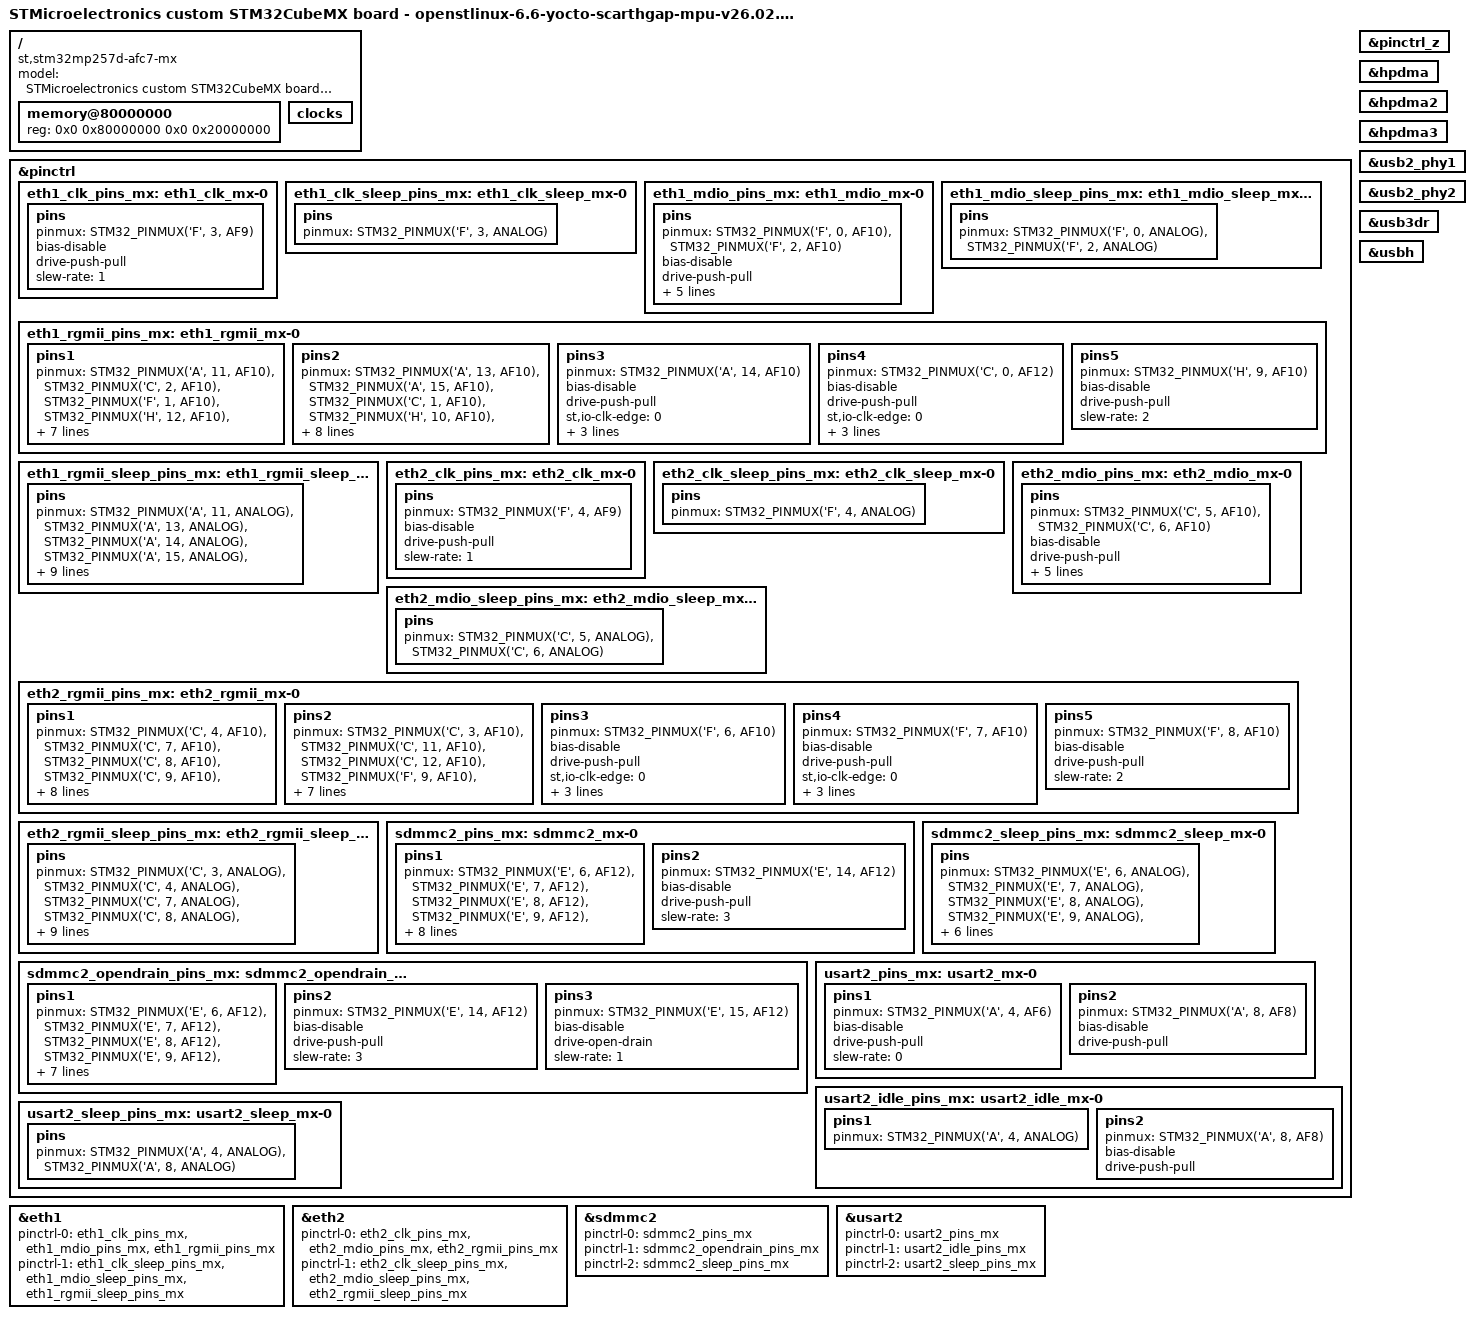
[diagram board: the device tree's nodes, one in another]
// SPDX-License-Identifier: (GPL-2.0-only OR BSD-3-Clause)
/*
 * Copyright (C) 2026, STMicroelectronics - All Rights Reserved
 * Author: STM32CubeMX code generation for STMicroelectronics.
 */

/* For more information on Device Tree configuration, please refer to
 * https://wiki.st.com/stm32mpu/wiki/Category:Device_tree_configuration
 */

/dts-v1/;

#include <dt-bindings/pinctrl/stm32-pinfunc.h>
#include "stm32mp257.dtsi"
#include "stm32mp257d-afc7-mx-resmem.dtsi"
#include "stm32mp25xxak-pinctrl.dtsi"

/* USER CODE BEGIN includes */
/* USER CODE END includes */

/ {
	model = "STMicroelectronics custom STM32CubeMX board - openstlinux-6.6-yocto-scarthgap-mpu-v26.02.18";
	compatible = "st,stm32mp257d-afc7-mx", "st,stm32mp257";

	memory@80000000 {
		device_type = "memory";
		reg = <0x0 0x80000000 0x0 0x20000000>;

		/* USER CODE BEGIN memory */
		/* USER CODE END memory */
	};

	/* USER CODE BEGIN root */
	/* USER CODE END root */

	clocks{

		/* USER CODE BEGIN clocks */
		/* USER CODE END clocks */
	};

}; /*root*/

&pinctrl {

	eth1_clk_pins_mx: eth1_clk_mx-0 {
		pins {
			pinmux = <STM32_PINMUX('F', 3, AF9)>; /* ETH1_CLK */
			bias-disable;
			drive-push-pull;
			slew-rate = <1>;
		};
	};

	eth1_clk_sleep_pins_mx: eth1_clk_sleep_mx-0 {
		pins {
			pinmux = <STM32_PINMUX('F', 3, ANALOG)>; /* ETH1_CLK */
		};
	};

	eth1_mdio_pins_mx: eth1_mdio_mx-0 {
		pins {
			pinmux = <STM32_PINMUX('F', 0, AF10)>, /* ETH1_MDC */
					 <STM32_PINMUX('F', 2, AF10)>; /* ETH1_MDIO */
			bias-disable;
			drive-push-pull;
			slew-rate = <1>;
			st,io-clk-edge = <0>;
			st,io-retime = <0>;
			st,io-delay-path = <0>;
			st,io-delay = <0>;
		};
	};

	eth1_mdio_sleep_pins_mx: eth1_mdio_sleep_mx-0 {
		pins {
			pinmux = <STM32_PINMUX('F', 0, ANALOG)>, /* ETH1_MDC */
					 <STM32_PINMUX('F', 2, ANALOG)>; /* ETH1_MDIO */
		};
	};

	eth1_rgmii_pins_mx: eth1_rgmii_mx-0 {
		pins1 {
			pinmux = <STM32_PINMUX('A', 11, AF10)>, /* ETH1_RGMII_RX_CTL */
					 <STM32_PINMUX('C', 2, AF10)>, /* ETH1_RGMII_RXD1 */
					 <STM32_PINMUX('F', 1, AF10)>, /* ETH1_RGMII_RXD0 */
					 <STM32_PINMUX('H', 12, AF10)>, /* ETH1_RGMII_RXD2 */
					 <STM32_PINMUX('H', 13, AF10)>; /* ETH1_RGMII_RXD3 */
			bias-disable;
			drive-push-pull;
			st,io-clk-edge = <1>;
			st,io-retime = <1>;
			st,io-delay-path = <0>;
			st,io-delay = <0>;
		};
		pins2 {
			pinmux = <STM32_PINMUX('A', 13, AF10)>, /* ETH1_RGMII_TX_CTL */
					 <STM32_PINMUX('A', 15, AF10)>, /* ETH1_RGMII_TXD0 */
					 <STM32_PINMUX('C', 1, AF10)>, /* ETH1_RGMII_TXD1 */
					 <STM32_PINMUX('H', 10, AF10)>, /* ETH1_RGMII_TXD2 */
					 <STM32_PINMUX('H', 11, AF10)>; /* ETH1_RGMII_TXD3 */
			bias-disable;
			drive-push-pull;
			slew-rate = <2>;
			st,io-clk-edge = <1>;
			st,io-retime = <1>;
			st,io-delay-path = <0>;
			st,io-delay = <0>;
		};
		pins3 {
			pinmux = <STM32_PINMUX('A', 14, AF10)>; /* ETH1_RGMII_RX_CLK */
			bias-disable;
			drive-push-pull;
			st,io-clk-edge = <0>;
			st,io-retime = <0>;
			st,io-delay-path = <1>;
			st,io-delay = <0>;
		};
		pins4 {
			pinmux = <STM32_PINMUX('C', 0, AF12)>; /* ETH1_RGMII_GTX_CLK */
			bias-disable;
			drive-push-pull;
			st,io-clk-edge = <0>;
			st,io-retime = <0>;
			st,io-delay-path = <0>;
			st,io-delay = <0>;
		};
		pins5 {
			pinmux = <STM32_PINMUX('H', 9, AF10)>; /* ETH1_RGMII_CLK125 */
			bias-disable;
			drive-push-pull;
			slew-rate = <2>;
		};
	};

	eth1_rgmii_sleep_pins_mx: eth1_rgmii_sleep_mx-0 {
		pins {
			pinmux = <STM32_PINMUX('A', 11, ANALOG)>, /* ETH1_RGMII_RX_CTL */
					 <STM32_PINMUX('A', 13, ANALOG)>, /* ETH1_RGMII_TX_CTL */
					 <STM32_PINMUX('A', 14, ANALOG)>, /* ETH1_RGMII_RX_CLK */
					 <STM32_PINMUX('A', 15, ANALOG)>, /* ETH1_RGMII_TXD0 */
					 <STM32_PINMUX('C', 0, ANALOG)>, /* ETH1_RGMII_GTX_CLK */
					 <STM32_PINMUX('C', 1, ANALOG)>, /* ETH1_RGMII_TXD1 */
					 <STM32_PINMUX('C', 2, ANALOG)>, /* ETH1_RGMII_RXD1 */
					 <STM32_PINMUX('F', 1, ANALOG)>, /* ETH1_RGMII_RXD0 */
					 <STM32_PINMUX('H', 9, ANALOG)>, /* ETH1_RGMII_CLK125 */
					 <STM32_PINMUX('H', 10, ANALOG)>, /* ETH1_RGMII_TXD2 */
					 <STM32_PINMUX('H', 11, ANALOG)>, /* ETH1_RGMII_TXD3 */
					 <STM32_PINMUX('H', 12, ANALOG)>, /* ETH1_RGMII_RXD2 */
					 <STM32_PINMUX('H', 13, ANALOG)>; /* ETH1_RGMII_RXD3 */
		};
	};

	eth2_clk_pins_mx: eth2_clk_mx-0 {
		pins {
			pinmux = <STM32_PINMUX('F', 4, AF9)>; /* ETH2_CLK */
			bias-disable;
			drive-push-pull;
			slew-rate = <1>;
		};
	};

	eth2_clk_sleep_pins_mx: eth2_clk_sleep_mx-0 {
		pins {
			pinmux = <STM32_PINMUX('F', 4, ANALOG)>; /* ETH2_CLK */
		};
	};

	eth2_mdio_pins_mx: eth2_mdio_mx-0 {
		pins {
			pinmux = <STM32_PINMUX('C', 5, AF10)>, /* ETH2_MDIO */
					 <STM32_PINMUX('C', 6, AF10)>; /* ETH2_MDC */
			bias-disable;
			drive-push-pull;
			slew-rate = <1>;
			st,io-clk-edge = <0>;
			st,io-retime = <0>;
			st,io-delay-path = <0>;
			st,io-delay = <0>;
		};
	};

	eth2_mdio_sleep_pins_mx: eth2_mdio_sleep_mx-0 {
		pins {
			pinmux = <STM32_PINMUX('C', 5, ANALOG)>, /* ETH2_MDIO */
					 <STM32_PINMUX('C', 6, ANALOG)>; /* ETH2_MDC */
		};
	};

	eth2_rgmii_pins_mx: eth2_rgmii_mx-0 {
		pins1 {
			pinmux = <STM32_PINMUX('C', 4, AF10)>, /* ETH2_RGMII_TX_CTL */
					 <STM32_PINMUX('C', 7, AF10)>, /* ETH2_RGMII_TXD0 */
					 <STM32_PINMUX('C', 8, AF10)>, /* ETH2_RGMII_TXD1 */
					 <STM32_PINMUX('C', 9, AF10)>, /* ETH2_RGMII_TXD2 */
					 <STM32_PINMUX('C', 10, AF10)>; /* ETH2_RGMII_TXD3 */
			bias-disable;
			drive-push-pull;
			slew-rate = <2>;
			st,io-clk-edge = <1>;
			st,io-retime = <1>;
			st,io-delay-path = <0>;
			st,io-delay = <0>;
		};
		pins2 {
			pinmux = <STM32_PINMUX('C', 3, AF10)>, /* ETH2_RGMII_RX_CTL */
					 <STM32_PINMUX('C', 11, AF10)>, /* ETH2_RGMII_RXD3 */
					 <STM32_PINMUX('C', 12, AF10)>, /* ETH2_RGMII_RXD1 */
					 <STM32_PINMUX('F', 9, AF10)>, /* ETH2_RGMII_RXD2 */
					 <STM32_PINMUX('G', 0, AF10)>; /* ETH2_RGMII_RXD0 */
			bias-disable;
			drive-push-pull;
			st,io-clk-edge = <1>;
			st,io-retime = <1>;
			st,io-delay-path = <0>;
			st,io-delay = <0>;
		};
		pins3 {
			pinmux = <STM32_PINMUX('F', 6, AF10)>; /* ETH2_RGMII_RX_CLK */
			bias-disable;
			drive-push-pull;
			st,io-clk-edge = <0>;
			st,io-retime = <0>;
			st,io-delay-path = <1>;
			st,io-delay = <0>;
		};
		pins4 {
			pinmux = <STM32_PINMUX('F', 7, AF10)>; /* ETH2_RGMII_GTX_CLK */
			bias-disable;
			drive-push-pull;
			st,io-clk-edge = <0>;
			st,io-retime = <0>;
			st,io-delay-path = <0>;
			st,io-delay = <0>;
		};
		pins5 {
			pinmux = <STM32_PINMUX('F', 8, AF10)>; /* ETH2_RGMII_CLK125 */
			bias-disable;
			drive-push-pull;
			slew-rate = <2>;
		};
	};

	eth2_rgmii_sleep_pins_mx: eth2_rgmii_sleep_mx-0 {
		pins {
			pinmux = <STM32_PINMUX('C', 3, ANALOG)>, /* ETH2_RGMII_RX_CTL */
					 <STM32_PINMUX('C', 4, ANALOG)>, /* ETH2_RGMII_TX_CTL */
					 <STM32_PINMUX('C', 7, ANALOG)>, /* ETH2_RGMII_TXD0 */
					 <STM32_PINMUX('C', 8, ANALOG)>, /* ETH2_RGMII_TXD1 */
					 <STM32_PINMUX('C', 9, ANALOG)>, /* ETH2_RGMII_TXD2 */
					 <STM32_PINMUX('C', 10, ANALOG)>, /* ETH2_RGMII_TXD3 */
					 <STM32_PINMUX('C', 11, ANALOG)>, /* ETH2_RGMII_RXD3 */
					 <STM32_PINMUX('C', 12, ANALOG)>, /* ETH2_RGMII_RXD1 */
					 <STM32_PINMUX('F', 6, ANALOG)>, /* ETH2_RGMII_RX_CLK */
					 <STM32_PINMUX('F', 7, ANALOG)>, /* ETH2_RGMII_GTX_CLK */
					 <STM32_PINMUX('F', 8, ANALOG)>, /* ETH2_RGMII_CLK125 */
					 <STM32_PINMUX('F', 9, ANALOG)>, /* ETH2_RGMII_RXD2 */
					 <STM32_PINMUX('G', 0, ANALOG)>; /* ETH2_RGMII_RXD0 */
		};
	};

	sdmmc2_pins_mx: sdmmc2_mx-0 {
		pins1 {
			pinmux = <STM32_PINMUX('E', 6, AF12)>, /* SDMMC2_D6 */
					 <STM32_PINMUX('E', 7, AF12)>, /* SDMMC2_D7 */
					 <STM32_PINMUX('E', 8, AF12)>, /* SDMMC2_D2 */
					 <STM32_PINMUX('E', 9, AF12)>, /* SDMMC2_D5 */
					 <STM32_PINMUX('E', 10, AF12)>, /* SDMMC2_D4 */
					 <STM32_PINMUX('E', 11, AF12)>, /* SDMMC2_D1 */
					 <STM32_PINMUX('E', 12, AF12)>, /* SDMMC2_D3 */
					 <STM32_PINMUX('E', 13, AF12)>, /* SDMMC2_D0 */
					 <STM32_PINMUX('E', 15, AF12)>; /* SDMMC2_CMD */
			bias-disable;
			drive-push-pull;
			slew-rate = <1>;
		};
		pins2 {
			pinmux = <STM32_PINMUX('E', 14, AF12)>; /* SDMMC2_CK */
			bias-disable;
			drive-push-pull;
			slew-rate = <3>;
		};
	};

	sdmmc2_opendrain_pins_mx: sdmmc2_opendrain_mx-0 {
		pins1 {
			pinmux = <STM32_PINMUX('E', 6, AF12)>, /* SDMMC2_D6 */
					 <STM32_PINMUX('E', 7, AF12)>, /* SDMMC2_D7 */
					 <STM32_PINMUX('E', 8, AF12)>, /* SDMMC2_D2 */
					 <STM32_PINMUX('E', 9, AF12)>, /* SDMMC2_D5 */
					 <STM32_PINMUX('E', 10, AF12)>, /* SDMMC2_D4 */
					 <STM32_PINMUX('E', 11, AF12)>, /* SDMMC2_D1 */
					 <STM32_PINMUX('E', 12, AF12)>, /* SDMMC2_D3 */
					 <STM32_PINMUX('E', 13, AF12)>; /* SDMMC2_D0 */
			bias-disable;
			drive-push-pull;
			slew-rate = <1>;
		};
		pins2 {
			pinmux = <STM32_PINMUX('E', 14, AF12)>; /* SDMMC2_CK */
			bias-disable;
			drive-push-pull;
			slew-rate = <3>;
		};
		pins3 {
			pinmux = <STM32_PINMUX('E', 15, AF12)>; /* SDMMC2_CMD */
			bias-disable;
			drive-open-drain;
			slew-rate = <1>;
		};
	};

	sdmmc2_sleep_pins_mx: sdmmc2_sleep_mx-0 {
		pins {
			pinmux = <STM32_PINMUX('E', 6, ANALOG)>, /* SDMMC2_D6 */
					 <STM32_PINMUX('E', 7, ANALOG)>, /* SDMMC2_D7 */
					 <STM32_PINMUX('E', 8, ANALOG)>, /* SDMMC2_D2 */
					 <STM32_PINMUX('E', 9, ANALOG)>, /* SDMMC2_D5 */
					 <STM32_PINMUX('E', 10, ANALOG)>, /* SDMMC2_D4 */
					 <STM32_PINMUX('E', 11, ANALOG)>, /* SDMMC2_D1 */
					 <STM32_PINMUX('E', 12, ANALOG)>, /* SDMMC2_D3 */
					 <STM32_PINMUX('E', 13, ANALOG)>, /* SDMMC2_D0 */
					 <STM32_PINMUX('E', 14, ANALOG)>, /* SDMMC2_CK */
					 <STM32_PINMUX('E', 15, ANALOG)>; /* SDMMC2_CMD */
		};
	};

	usart2_pins_mx: usart2_mx-0 {
		pins1 {
			pinmux = <STM32_PINMUX('A', 4, AF6)>; /* USART2_TX */
			bias-disable;
			drive-push-pull;
			slew-rate = <0>;
		};
		pins2 {
			pinmux = <STM32_PINMUX('A', 8, AF8)>; /* USART2_RX */
			bias-disable;
			drive-push-pull;
		};
	};

	usart2_idle_pins_mx: usart2_idle_mx-0 {
		pins1 {
			pinmux = <STM32_PINMUX('A', 4, ANALOG)>; /* USART2_TX */
		};
		pins2 {
			pinmux = <STM32_PINMUX('A', 8, AF8)>; /* USART2_RX */
			bias-disable;
			drive-push-pull;
		};
	};

	usart2_sleep_pins_mx: usart2_sleep_mx-0 {
		pins {
			pinmux = <STM32_PINMUX('A', 4, ANALOG)>, /* USART2_TX */
					 <STM32_PINMUX('A', 8, ANALOG)>; /* USART2_RX */
		};
	};

	/* USER CODE BEGIN pinctrl */
	/* USER CODE END pinctrl */
};

&pinctrl_z {

	/* USER CODE BEGIN pinctrl_z */
	/* USER CODE END pinctrl_z */
};

&eth1 {
	pinctrl-names = "default", "sleep";
	pinctrl-0 = <&eth1_clk_pins_mx>, <&eth1_mdio_pins_mx>, <&eth1_rgmii_pins_mx>;
	pinctrl-1 = <&eth1_clk_sleep_pins_mx>, <&eth1_mdio_sleep_pins_mx>, <&eth1_rgmii_sleep_pins_mx>;
	status = "okay";

	/* USER CODE BEGIN eth1 */
	/* USER CODE END eth1 */
};

&eth2 {
	pinctrl-names = "default", "sleep";
	pinctrl-0 = <&eth2_clk_pins_mx>, <&eth2_mdio_pins_mx>, <&eth2_rgmii_pins_mx>;
	pinctrl-1 = <&eth2_clk_sleep_pins_mx>, <&eth2_mdio_sleep_pins_mx>, <&eth2_rgmii_sleep_pins_mx>;
	status = "okay";

	/* USER CODE BEGIN eth2 */
	/* USER CODE END eth2 */
};

&hpdma {
	status = "okay";

	/* USER CODE BEGIN hpdma */
	/* USER CODE END hpdma */
};

&hpdma2 {
	status = "okay";

	/* USER CODE BEGIN hpdma2 */
	/* USER CODE END hpdma2 */
};

&hpdma3 {
	status = "okay";

	/* USER CODE BEGIN hpdma3 */
	/* USER CODE END hpdma3 */
};

&sdmmc2 {
	pinctrl-names = "default", "opendrain", "sleep";
	pinctrl-0 = <&sdmmc2_pins_mx>;
	pinctrl-1 = <&sdmmc2_opendrain_pins_mx>;
	pinctrl-2 = <&sdmmc2_sleep_pins_mx>;
	status = "okay";

	/* USER CODE BEGIN sdmmc2 */
	/* USER CODE END sdmmc2 */
};

&usart2 {
	pinctrl-names = "default", "idle", "sleep";
	pinctrl-0 = <&usart2_pins_mx>;
	pinctrl-1 = <&usart2_idle_pins_mx>;
	pinctrl-2 = <&usart2_sleep_pins_mx>;
	status = "okay";

	/* USER CODE BEGIN usart2 */
	/* USER CODE END usart2 */
};

&usb2_phy1 {
	status = "okay";

	/* USER CODE BEGIN usb2_phy1 */
	/* USER CODE END usb2_phy1 */
};

&usb2_phy2 {
	status = "okay";

	/* USER CODE BEGIN usb2_phy2 */
	/* USER CODE END usb2_phy2 */
};

&usb3dr {
	status = "okay";

	/* USER CODE BEGIN usb3dr */
	/* USER CODE END usb3dr */
};

&usbh {
	status = "okay";

	/* USER CODE BEGIN usbh */
	/* USER CODE END usbh */
};

/* USER CODE BEGIN addons */
/* USER CODE END addons */

